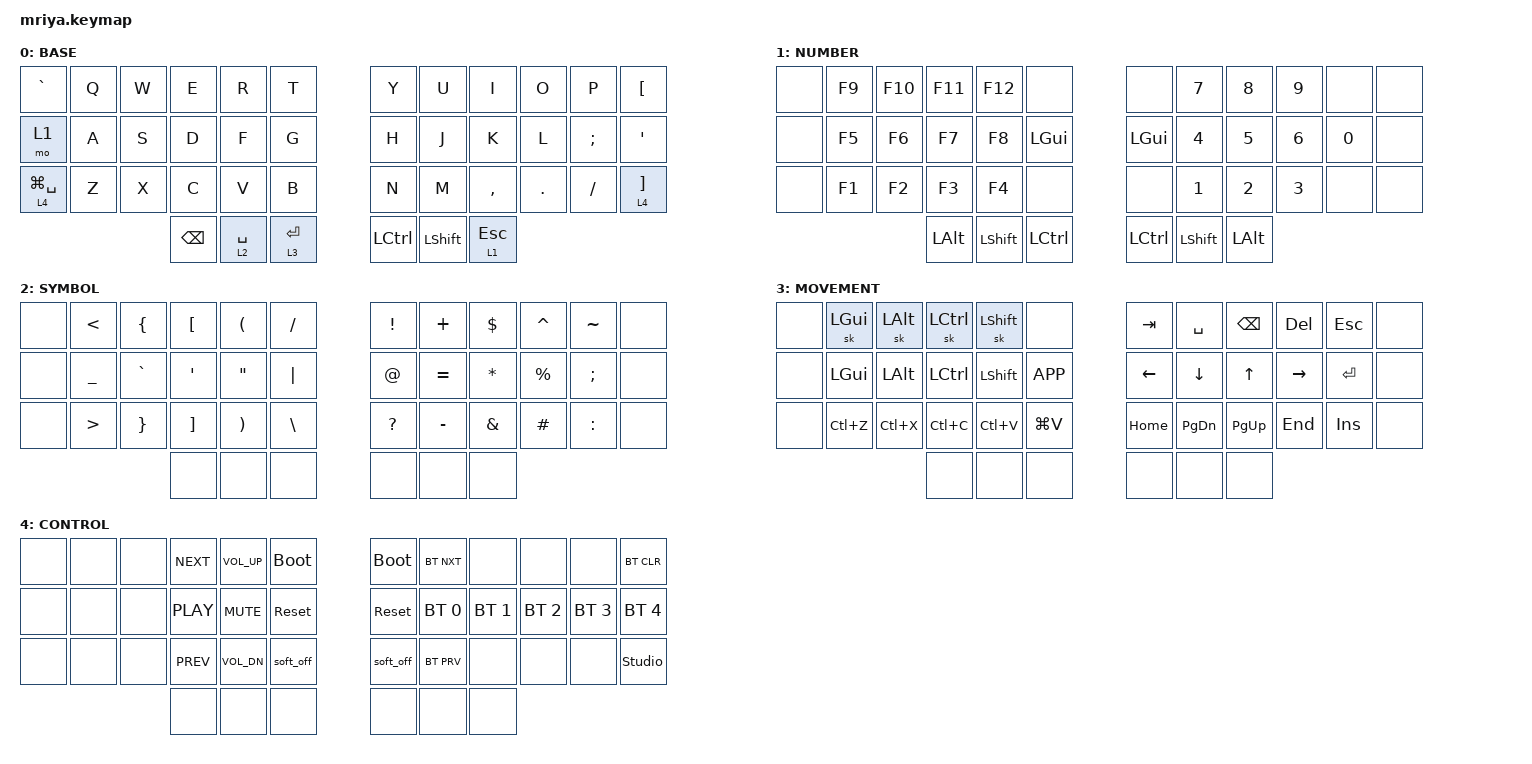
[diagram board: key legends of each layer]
/*
 * Copyright (c) 2020 The ZMK Contributors
 *
 * SPDX-License-Identifier: MIT
 */

#include <behaviors.dtsi>
#include <dt-bindings/zmk/keys.h>
#include <dt-bindings/zmk/bt.h>
#include <dt-bindings/zmk/ext_power.h>

#define BASE     0
#define NUMBER   1
#define SYMBOL   2
#define MOVEMENT 3
#define CONTROL  4

&lt {
    flavor = "balanced";
    tapping-term-ms = <220>;
    quick-tap-ms = <175>;
};

&mt {
    flavor = "balanced";
    tapping-term-ms = <280>;
    quick-tap-ms = <175>;
};

&sk {
    release-after-ms = <1000>;
    quick-release;
};

/ {
    keymap {
        compatible = "zmk,keymap";

// ▄▄▄▄▄▄▄▄▄▄▄▄▄▄▄▄▄▄▄▄▄▄▄▄▄▄▄▄▄▄▄▄▄▄▄▄▄▄▄▄▄▄▄▄▄▄▄▄▄▄▄▄▄▄▄▄▄▄▄▄▄▄▄▄▄▄▄▄▄▄▄▄▄▄▄▄▄▄▄▄▄▄▄▄▄▄▄▄▄▄▄▄▄▄▄▄▄▄▄▄▄▄▄▄▄▄▄▄▄▄▄▄▄▄


        base_layer {
// ┌────────────────────────────────────────────┐
label= "BASE"                                   ;
// └────────────────────────────────────────────┘
/*
┌───────┬───────┬───────┬───────┬───────┬───────┐                   ┌───────┬───────┬───────┬───────┬───────┬───────┐
│   `   │   Q   │   W   │   E   │   R   │   T   │                   │   Y   │   U   │   I   │   O   │   P   │   [   │
├───────┼───────┼───────┼───────┼───────┼───────┤                   ├───────┼───────┼───────┼───────┼───────┼───────┤
│NUMBER │   A   │   S   │   D   │   F   │   G   │                   │   H   │   J   │   K   │   L   │   ;   │   '   │
├───────┼───────┼───────┼───────┼───────┼───────┤                   ├───────┼───────┼───────┼───────┼───────┼───────┤
│LANG/4 │   Z   │   X   │   C   │   V   │   B   │                   │   N   │   M   │   ,   │   .   │   /   │  ]/4  │
└───────┴───────┴───────┴───────┼───────┼───────┼───────┐   ┌───────┼───────┼───────┼───────┴───────┴───────┴───────┘
                                │BSPACE │SPACE/2│ENTER/3│   │ LCTRL │ LSHFT │ ESC/1 │
                                └───────┴───────┴───────┘   └───────┴───────┴───────┘
*/
bindings = <
 
&kp GRAVE       &kp Q        &kp W        &kp E           &kp R         &kp T       &kp Y       &kp U         &kp I         &kp O       &kp P           &kp LBKT
&mo 1           &kp A        &kp S        &kp D           &kp F         &kp G       &kp H       &kp J         &kp K         &kp L       &kp SEMI        &kp SQT
&lt 4 LG(SPACE) &kp Z        &kp X        &kp C           &kp V         &kp B       &kp N       &kp M         &kp COMMA     &kp DOT     &kp FSLH        &lt 4 RBKT
                                          &kp BSPC        &lt 2 SPACE   &lt 3 ENTER &kp LCTRL   &kp LSHFT     &lt 1 ESC
            >;
        };
        
// ▄▄▄▄▄▄▄▄▄▄▄▄▄▄▄▄▄▄▄▄▄▄▄▄▄▄▄▄▄▄▄▄▄▄▄▄▄▄▄▄▄▄▄▄▄▄▄▄▄▄▄▄▄▄▄▄▄▄▄▄▄▄▄▄▄▄▄▄▄▄▄▄▄▄▄▄▄▄▄▄▄▄▄▄▄▄▄▄▄▄▄▄▄▄▄▄▄▄▄▄▄▄▄▄▄▄▄▄▄▄▄▄▄▄


        number_layer {
// ┌────────────────────────────────────────────┐
label= "NUMBER"                                 ;
// └────────────────────────────────────────────┘
/*
┌───────┬───────┬───────┬───────┬───────┬───────┐                   ┌───────┬───────┬───────┬───────┬───────┬───────┐
│       │  F9   │  F10  │  F11  │  F12  │       │                   │       │   7   │   8   │   9   │       │       │
├───────┼───────┼───────┼───────┼───────┼───────┤                   ├───────┼───────┼───────┼───────┼───────┼───────┤
│       │  F5   │  F6   │  F7   │  F8   │ LGUI  │                   │ LGUI  │   4   │   5   │   6   │   0   │       │
├───────┼───────┼───────┼───────┼───────┼───────┤                   ├───────┼───────┼───────┼───────┼───────┼───────┤
│       │  F1   │  F2   │  F3   │  F4   │       │                   │       │   1   │   2   │   3   │       │       │
└───────┴───────┴───────┴───────┼───────┼───────┼───────┐   ┌───────┼───────┼───────┼───────┴───────┴───────┴───────┘
                                │ LALT  │ LSHFT │ LCTRL │   │ LCTRL │ LSHFT │ LALT  │
                                └───────┴───────┴───────┘   └───────┴───────┴───────┘
*/
bindings = <

&none       &kp F9    &kp F10   &kp F11     &kp F12           &none           &none      &kp N7          &kp N8         &kp N9       &none         &none
&none       &kp F5    &kp F6    &kp F7      &kp F8            &kp LGUI        &kp LGUI   &kp N4          &kp N5         &kp N6       &kp N0        &none
&none       &kp F1    &kp F2    &kp F3      &kp F4            &none           &none      &kp N1          &kp N2         &kp N3       &none         &none
                                &kp LALT    &kp LSHFT         &kp LCTRL       &kp LCTRL  &kp LSHFT       &kp LALT
            >;
        };

// ▄▄▄▄▄▄▄▄▄▄▄▄▄▄▄▄▄▄▄▄▄▄▄▄▄▄▄▄▄▄▄▄▄▄▄▄▄▄▄▄▄▄▄▄▄▄▄▄▄▄▄▄▄▄▄▄▄▄▄▄▄▄▄▄▄▄▄▄▄▄▄▄▄▄▄▄▄▄▄▄▄▄▄▄▄▄▄▄▄▄▄▄▄▄▄▄▄▄▄▄▄▄▄▄▄▄▄▄▄▄▄▄▄▄


        symbol_layer {
// ┌────────────────────────────────────────────┐
label= "SYMBOL"                                 ;
// └────────────────────────────────────────────┘
/*
┌───────┬───────┬───────┬───────┬───────┬───────┐                   ┌───────┬───────┬───────┬───────┬───────┬───────┐
│       │   <   │   {   │   [   │   (   │   /   │                   │   !   │   +   │   $   │   ^   │   ~   │       │
├───────┼───────┼───────┼───────┼───────┼───────┤                   ├───────┼───────┼───────┼───────┼───────┼───────┤
│       │   _   │   `   │   '   │   "   │   |   │                   │   @   │   =   │   *   │   %   │   ;   │       │
├───────┼───────┼───────┼───────┼───────┼───────┤                   ├───────┼───────┼───────┼───────┼───────┼───────┤
│       │   >   │   }   │   ]   │   )   │   \   │                   │   ?   │   -   │   &   │   #   │   :   │       │
└───────┴───────┴───────┴───────┼───────┼───────┼───────┐   ┌───────┼───────┼───────┼───────┴───────┴───────┴───────┘
                                │       │       │       │   │       │       │       │
                                └───────┴───────┴───────┘   └───────┴───────┴───────┘
*/
bindings = <

&none       &kp LT    &kp LBRC  &kp LBKT    &kp LPAR          &kp FSLH        &kp EXCL   &kp PLUS        &kp DOLLAR       &kp CARET    &kp TILDE     &none
&none       &kp UNDER &kp GRAVE &kp SQT     &kp DQT           &kp PIPE        &kp AT     &kp EQUAL       &kp ASTRK        &kp PERCENT  &kp SEMI      &none
&none       &kp GT    &kp RBRC  &kp RBKT    &kp RPAR          &kp BSLH        &kp QMARK  &kp MINUS       &kp AMPS         &kp HASH     &kp COLON     &none
                                &none       &none             &none           &none      &none           &none
            >;
        };

// ▄▄▄▄▄▄▄▄▄▄▄▄▄▄▄▄▄▄▄▄▄▄▄▄▄▄▄▄▄▄▄▄▄▄▄▄▄▄▄▄▄▄▄▄▄▄▄▄▄▄▄▄▄▄▄▄▄▄▄▄▄▄▄▄▄▄▄▄▄▄▄▄▄▄▄▄▄▄▄▄▄▄▄▄▄▄▄▄▄▄▄▄▄▄▄▄▄▄▄▄▄▄▄▄▄▄▄▄▄▄▄▄▄▄


        movement_layer {
// ┌────────────────────────────────────────────┐
label= "MOVEMENT"                               ;
// └────────────────────────────────────────────┘
/*
┌───────┬───────┬───────┬───────┬───────┬───────┐                   ┌───────┬───────┬───────┬───────┬───────┬───────┐
│       │S_LGUI │S_LALT │S_LCTRL│S_LSHFT│       │                   │  TAB  │ SPACE │BSPACE │  DEL  │  ESC  │       │
├───────┼───────┼───────┼───────┼───────┼───────┤                   ├───────┼───────┼───────┼───────┼───────┼───────┤
│       │ LGUI  │ LALT  │ LCTRL │ LSHFT │  APP  │                   │   ←   │   ↓   │   ↑   │   →   │ ENTER │       │
├───────┼───────┼───────┼───────┼───────┼───────┤                   ├───────┼───────┼───────┼───────┼───────┼───────┤
│       │CTRL+Z │CTRL+X │CTRL+C │CTRL+V │ WIN+V │                   │ HOME  │ PGDN  │ PGUP  │  END  │  INS  │       │
└───────┴───────┴───────┴───────┼───────┼───────┼───────┐   ┌───────┼───────┼───────┼───────┴───────┴───────┴───────┘
                                │       │       │       │   │       │       │       │
                                └───────┴───────┴───────┘   └───────┴───────┴───────┘
*/
bindings = <

&none       &sk LGUI  &sk LALT  &sk LCTRL   &sk LSHFT         &none           &kp TAB    &kp SPACE       &kp BSPC         &kp DEL      &kp ESC       &none
&none       &kp LGUI  &kp LALT  &kp LCTRL   &kp LSHFT         &kp K_APP       &kp LEFT   &kp DOWN        &kp UP           &kp RIGHT    &kp ENTER     &none
&none       &kp LC(Z) &kp LC(X) &kp LC(C)   &kp LC(V)         &kp LG(V)       &kp HOME   &kp PG_DN       &kp PG_UP        &kp END      &kp INSERT    &none
                                &none       &none             &none           &none      &none           &none
            >;
        };

// ▄▄▄▄▄▄▄▄▄▄▄▄▄▄▄▄▄▄▄▄▄▄▄▄▄▄▄▄▄▄▄▄▄▄▄▄▄▄▄▄▄▄▄▄▄▄▄▄▄▄▄▄▄▄▄▄▄▄▄▄▄▄▄▄▄▄▄▄▄▄▄▄▄▄▄▄▄▄▄▄▄▄▄▄▄▄▄▄▄▄▄▄▄▄▄▄▄▄▄▄▄▄▄▄▄▄▄▄▄▄▄▄▄▄


        control_layer {
// ┌────────────────────────────────────────────┐
label= "CONTROL"                                ;
// └────────────────────────────────────────────┘
/*
┌───────┬───────┬───────┬───────┬───────┬───────┐                   ┌───────┬───────┬───────┬───────┬───────┬───────┐
│       │       │       │ NEXT  │VOL_UP │ BOOT  │                   | BOOT  │BT_NEXT│       │       │       │BT_CLR │
├───────┼───────┼───────┼───────┼───────┼───────┤                   ├───────┼───────┼───────┼───────┼───────┼───────┤
│       │       │       │ PLAY  │ MUTE  │ RESET │                   │ RESET │  BT0  │  BT1  │  BT2  │  BT3  │  BT4  │
├───────┼───────┼───────┼───────┼───────┼───────┤                   ├───────┼───────┼───────┼───────┼───────┼───────┤
│       │       │       │ PREV  │VOL_DN │ POWER │                   │ POWER |BT_PREV│       │       │       │STUDIO │
└───────┴───────┴───────┴───────┼───────┼───────┼───────┐   ┌───────┼───────┼───────┼───────┴───────┴───────┴───────┘
                                │       │       │       │   │       │       │       │
                                └───────┴───────┴───────┘   └───────┴───────┴───────┘
*/
bindings = <

&none       &none     &none     &kp C_NEXT  &kp K_VOL_UP      &bootloader     &bootloader&bt BT_NXT      &none          &none        &none         &bt BT_CLR
&none       &none     &none     &kp C_PLAY  &kp K_MUTE        &sys_reset      &sys_reset &bt BT_SEL 0    &bt BT_SEL 1   &bt BT_SEL 2 &bt BT_SEL 3  &bt BT_SEL 4
&none       &none     &none     &kp C_PREV  &kp K_VOL_DN      &soft_off       &soft_off  &bt BT_PRV      &none          &none        &none         &studio_unlock
                                &none       &none             &none           &none      &none           &none
            >;
        };

    };
};
